# MKE16F16 register map
Vendor: Freescale Semiconductor, Inc.; Series: Kinetis_E; File version: 1.6
CPU: CM4 r0p1, little endian, no MPU, FPU, VTOR, 4 interrupt priority bits
Registers are 32-bit, read-write, reset 0x0 unless marked. A register's access mark holds for its fields unless they carry their own. Offsets are from the block's base; [hi:lo] are bit positions; {n}, {i} and the like mark numbered series; 'fields as' and 'values as' point back to an identical list.

## MSCM
Base 0x40001000; register names take the prefix MSCM_
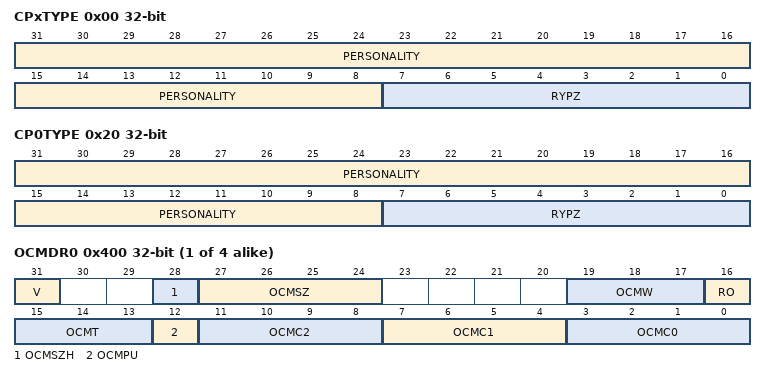
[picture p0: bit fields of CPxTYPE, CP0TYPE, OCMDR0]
0x00 CPxTYPE ro — Processor X Type Register
  [31:8] PERSONALITY — Processor x Personality
  [7:0] RYPZ — Processor x Revision
0x04 CPxNUM ro — Processor X Number Register
  [0] CPN — Processor x Number
0x08 CPxMASTER ro — Processor X Master Register
  [5:0] PPN — Processor x Physical Port Number
0x0C CPxCOUNT ro — Processor X Count Register
  [1:0] PCNT — Processor Count
{0x10+4i} CPxCFG{i} (i=0..3) ro reset not defined — Processor X Configuration Register
  [31:24] ICSZ — Level 1 Instruction Cache Size
0x20 CP0TYPE ro — Processor 0 Type Register
  fields as CPxTYPE
0x24 CP0NUM ro — Processor 0 Number Register
  [0] CPN — Processor x Number
0x28 CP0MASTER ro — Processor 0 Master Register
  [5:0] PPN — Processor x Physical Port Number
0x2C CP0COUNT ro — Processor 0 Count Register
  [1:0] PCNT — Processor Count
{0x30+4i} CP0CFG{i} (i=0..3) ro reset not defined — Processor 0 Configuration Register
  [31:24] ICSZ — Level 1 Instruction Cache Size
{0x400+4i} OCMDR{i} (i=0..3) reset not defined — On-Chip Memory Descriptor Register
  [31] V ro — OCMEM Valid bit. This read-only field defines the validity (presence) of the on-chip memory
    0=OCMEMn is not present; 1=OCMEMn is present
  [28] OCMSZH ro — OCMEM Size "Hole"
    0=OCMEMn is a power-of-2 capacity; 1=OCMEMn is not a power-of-2, with a capacity is 0.75 * OCMSZ
  [27:24] OCMSZ ro — OCMEM Size
    0=no OCMEMn; 3=4KB OCMEMn; 4=8KB OCMEMn; 5=16KB OCMEMn; 6=32KB OCMEMn; 7=64KB OCMEMn; 8=128KB OCMEMn; 9=256KB OCMEMn; 10=512KB OCMEMn; 11=1024KB OCMEMn; 12=2048KB OCMEMn; 13=4096KB OCMEMn; 14=8192KB OCMEMn; 15=16384KB OCMEMn
  [19:17] OCMW ro — OCMEM datapath Width. This read-only field defines the width of the on-chip memory:
    2=OCMEMn 32-bits wide; 3=OCMEMn 64-bits wide; 4=OCMEMn 128-bits wide; 5=OCMEMn 256-bits wide
  [16] RO ro — Read-Only
    0=writes to the OCMDRn[11:0] are allowed; 1=writes to the OCMDRn[11:0] are ignored
  [15:13] OCMT ro — OCMEM Type. This field defines the type of the on-chip memory:
    3=OCMEMn is a ROM; 4=OCMEMn is a program flash; 5=OCMEMn is a data flash; 6=OCMEMn is an EEE
  [12] OCMPU ro — OCMEM Memory Protection Unit
    0=OCMEMn is not protected by an MPU; 1=OCMEMn is protected by an MPU
  [11:8] OCMC2 — OCMEM Control Field 2
  [7:4] OCMC1 — OCMEM Control Field 1
  [3:0] OCMC0 — OCMEM Control Field 0

## DMAMUX — DMA channel multiplexor
Base 0x40021000; register names take the prefix DMAMUX_
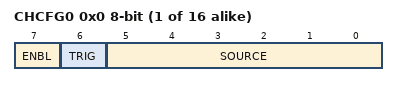
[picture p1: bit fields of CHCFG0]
{0x0+i} CHCFG{i} (i=0..15) 8-bit — Channel Configuration register
  [7] ENBL — DMA Channel Enable
    0=DMA channel is disabled. This mode is primarily used during configuration of the DMAMux. The DMA has separate channel enables/disables, which should be used to disable or reconfigure a DMA channel.; 1=DMA channel is enabled
  [6] TRIG — DMA Channel Trigger Enable
    0=Triggering is disabled. If triggering is disabled and ENBL is set, the DMA Channel will simply route the specified source to the DMA channel. (Normal mode); 1=Triggering is enabled. If triggering is enabled and ENBL is set, the DMAMUX is in Periodic Trigger mode.
  [5:0] SOURCE — DMA Channel Source (Slot)

## CRC — Cyclic Redundancy Check
Base 0x40032000; register names take the prefix CRC_
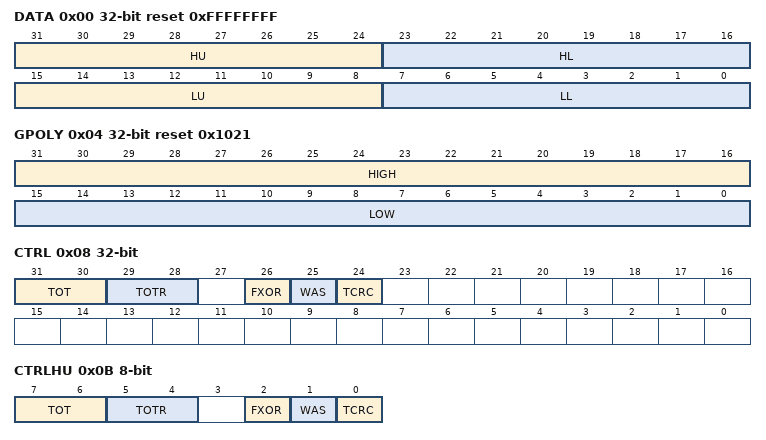
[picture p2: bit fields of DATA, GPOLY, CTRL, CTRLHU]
0x00 DATA reset 0xFFFFFFFF (CRC view) — CRC Data register
  [31:24] HU — CRC High Upper Byte
  [23:16] HL — CRC High Lower Byte
  [15:8] LU — CRC Low Upper Byte
  [7:0] LL — CRC Low Lower Byte
0x00 DATAL 16-bit reset 0xFFFF (CRC view) — CRC_DATAL register.
  [15:0] DATAL — DATAL stores the lower 16 bits of the 16/32 bit CRC
0x00 DATALL 8-bit reset 0xFF (CRC view) — CRC_DATALL register.
  [7:0] DATALL — CRCLL stores the first 8 bits of the 32 bit DATA
0x01 DATALU 8-bit reset 0xFF — CRC_DATALU register.
  [7:0] DATALU — DATALL stores the second 8 bits of the 32 bit CRC
0x02 DATAH 16-bit reset 0xFFFF (CRC view) — CRC_DATAH register.
  [15:0] DATAH — DATAH stores the high 16 bits of the 16/32 bit CRC
0x02 DATAHL 8-bit reset 0xFF (CRC view) — CRC_DATAHL register.
  [7:0] DATAHL — DATAHL stores the third 8 bits of the 32 bit CRC
0x03 DATAHU 8-bit reset 0xFF — CRC_DATAHU register.
  [7:0] DATAHU — DATAHU stores the fourth 8 bits of the 32 bit CRC
0x04 GPOLY reset 0x1021 (CRC view) — CRC Polynomial register
  [31:16] HIGH — High Polynominal Half-word
  [15:0] LOW — Low Polynominal Half-word
0x04 GPOLYL 16-bit reset 0xFFFF (CRC view) — CRC_GPOLYL register.
  [15:0] GPOLYL — POLYL stores the lower 16 bits of the 16/32 bit CRC polynomial value
0x04 GPOLYLL 8-bit reset 0xFF (CRC view) — CRC_GPOLYLL register.
  [7:0] GPOLYLL — POLYLL stores the first 8 bits of the 32 bit CRC
0x05 GPOLYLU 8-bit reset 0xFF — CRC_GPOLYLU register.
  [7:0] GPOLYLU — POLYLL stores the second 8 bits of the 32 bit CRC
0x06 GPOLYH 16-bit reset 0xFFFF (CRC view) — CRC_GPOLYH register.
  [15:0] GPOLYH — POLYH stores the high 16 bits of the 16/32 bit CRC polynomial value
0x06 GPOLYHL 8-bit reset 0xFF (CRC view) — CRC_GPOLYHL register.
  [7:0] GPOLYHL — POLYHL stores the third 8 bits of the 32 bit CRC
0x07 GPOLYHU 8-bit reset 0xFF — CRC_GPOLYHU register.
  [7:0] GPOLYHU — POLYHU stores the fourth 8 bits of the 32 bit CRC
0x08 CTRL — CRC Control register
  [31:30] TOT — Type Of Transpose For Writes
    0=No transposition; 1=Bits in bytes are transposed; bytes are not transposed; 2=Both bits in bytes and bytes are transposed; 3=Only bytes are transposed; no bits in a byte are transposed
  [29:28] TOTR — Type Of Transpose For Read
    values as TOT
  [26] FXOR — Complement Read Of CRC Data Register
    0=No XOR on reading; 1=Invert or complement the read value of the CRC Data register
  [25] WAS — Write CRC Data Register As Seed
    0=Writes to the CRC data register are data values; 1=Writes to the CRC data register are seed values
  [24] TCRC — Width of CRC protocol.
    0=16-bit CRC protocol; 1=32-bit CRC protocol
0x0B CTRLHU 8-bit — CRC_CTRLHU register.
  [7:6] TOT
    0=No Transposition; 1=Bits in bytes are transposed, bytes are not transposed; 2=Both bits in bytes and bytes are transposed; 3=Only bytes are transposed; no bits in a byte are transposed
  [5:4] TOTR
    values as TOT
  [2] FXOR
    0=No XOR on reading; 1=Invert or complement the read value of CRC data register
  [1] WAS
    0=Writes to CRC data register are data values; 1=Writes to CRC data reguster are seed values
  [0] TCRC
    0=16-bit CRC protocol; 1=32-bit CRC protocol

## Notices in the file
Redistribution and use in source and binary forms, with or without modification,
are permitted provided that the following conditions are met:
o Redistributions of source code must retain the above copyright notice, this list
of conditions and the following disclaimer.
o Redistributions in binary form must reproduce the above copyright notice, this
list of conditions and the following disclaimer in the documentation and/or
other materials provided with the distribution.
o Neither the name of Freescale Semiconductor, Inc. nor the names of its
contributors may be used to endorse or promote products derived from this
software without specific prior written permission.
THIS SOFTWARE IS PROVIDED BY THE COPYRIGHT HOLDERS AND CONTRIBUTORS "AS IS" AND
ANY EXPRESS OR IMPLIED WARRANTIES, INCLUDING, BUT NOT LIMITED TO, THE IMPLIED
WARRANTIES OF MERCHANTABILITY AND FITNESS FOR A PARTICULAR PURPOSE ARE
DISCLAIMED. IN NO EVENT SHALL THE COPYRIGHT HOLDER OR CONTRIBUTORS BE LIABLE FOR
ANY DIRECT, INDIRECT, INCIDENTAL, SPECIAL, EXEMPLARY, OR CONSEQUENTIAL DAMAGES
(INCLUDING, BUT NOT LIMITED TO, PROCUREMENT OF SUBSTITUTE GOODS OR SERVICES;
LOSS OF USE, DATA, OR PROFITS; OR BUSINESS INTERRUPTION) HOWEVER CAUSED AND ON
ANY THEORY OF LIABILITY, WHETHER IN CONTRACT, STRICT LIABILITY, OR TORT
(INCLUDING NEGLIGENCE OR OTHERWISE) ARISING IN ANY WAY OUT OF THE USE OF THIS
SOFTWARE, EVEN IF ADVISED OF THE POSSIBILITY OF SUCH DAMAGE.
